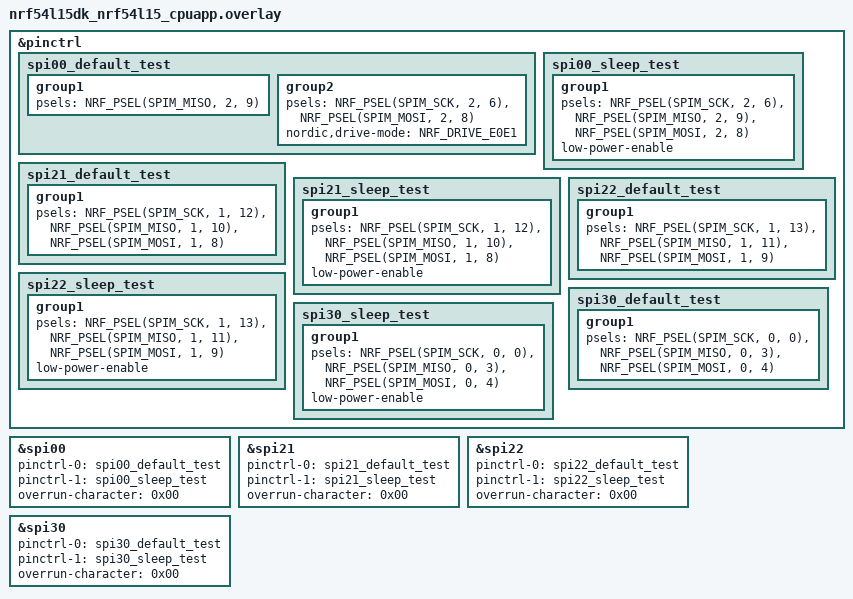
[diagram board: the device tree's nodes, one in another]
/*
 * Copyright (c) 2025 Nordic Semiconductor ASA
 *
 * SPDX-License-Identifier: LicenseRef-Nordic-5-Clause
 */

&pinctrl {
	spi00_default_test: spi00_default_test {
		group1 {
			psels = <NRF_PSEL(SPIM_MISO, 2, 9)>;
		};

		group2 {
			psels = <NRF_PSEL(SPIM_SCK, 2, 6)>,
				<NRF_PSEL(SPIM_MOSI, 2, 8)>;
			nordic,drive-mode = <NRF_DRIVE_E0E1>;
		};
	};

	spi00_sleep_test: spi00_sleep_test {
		group1 {
			psels = <NRF_PSEL(SPIM_SCK, 2, 6)>,
				<NRF_PSEL(SPIM_MISO, 2, 9)>,
				<NRF_PSEL(SPIM_MOSI, 2, 8)>;
			low-power-enable;
		};
	};

	spi21_default_test: spi21_default_test {
		group1 {
			psels = <NRF_PSEL(SPIM_SCK, 1, 12)>,
				<NRF_PSEL(SPIM_MISO, 1, 10)>,
				<NRF_PSEL(SPIM_MOSI, 1, 8)>;
		};
	};

	spi21_sleep_test: spi21_sleep_test {
		group1 {
			psels = <NRF_PSEL(SPIM_SCK, 1, 12)>,
				<NRF_PSEL(SPIM_MISO, 1, 10)>,
				<NRF_PSEL(SPIM_MOSI, 1, 8)>;
			low-power-enable;
		};
	};

	spi22_default_test: spi22_default_test {
		group1 {
			psels = <NRF_PSEL(SPIM_SCK, 1, 13)>,
				<NRF_PSEL(SPIM_MISO, 1, 11)>,
				<NRF_PSEL(SPIM_MOSI, 1, 9)>;
		};
	};

	spi22_sleep_test: spi22_sleep_test {
		group1 {
			psels = <NRF_PSEL(SPIM_SCK, 1, 13)>,
				<NRF_PSEL(SPIM_MISO, 1, 11)>,
				<NRF_PSEL(SPIM_MOSI, 1, 9)>;
			low-power-enable;
		};
	};

	spi30_default_test: spi30_default_test {
		group1 {
			psels = <NRF_PSEL(SPIM_SCK, 0, 0)>,
				<NRF_PSEL(SPIM_MISO, 0, 3)>,
				<NRF_PSEL(SPIM_MOSI, 0, 4)>;
		};
	};

	spi30_sleep_test: spi30_sleep_test {
		group1 {
			psels = <NRF_PSEL(SPIM_SCK, 0, 0)>,
				<NRF_PSEL(SPIM_MISO, 0, 3)>,
				<NRF_PSEL(SPIM_MOSI, 0, 4)>;
			low-power-enable;
		};
	};
};

/delete-node/ &mx25r64;

&spi00 {
	status = "okay";
	pinctrl-0 = <&spi00_default_test>;
	pinctrl-1 = <&spi00_sleep_test>;
	pinctrl-names = "default", "sleep";
	overrun-character = <0x00>;
};

/* spi20 inaccessible due to console on uart20 */

&spi21 {
	status = "okay";
	pinctrl-0 = <&spi21_default_test>;
	pinctrl-1 = <&spi21_sleep_test>;
	pinctrl-names = "default", "sleep";
	overrun-character = <0x00>;
};

&spi22 {
	status = "okay";
	pinctrl-0 = <&spi22_default_test>;
	pinctrl-1 = <&spi22_sleep_test>;
	pinctrl-names = "default", "sleep";
	overrun-character = <0x00>;
};

&spi30 {
	status = "okay";
	pinctrl-0 = <&spi30_default_test>;
	pinctrl-1 = <&spi30_sleep_test>;
	pinctrl-names = "default", "sleep";
	overrun-character = <0x00>;
};
